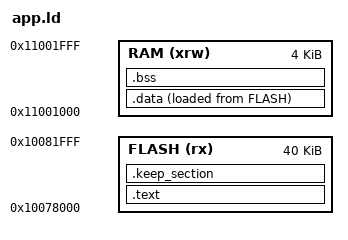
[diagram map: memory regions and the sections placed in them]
/*
 * Memory Spaces Definitions.
 *
 * Need modifying for a specific board. 
 *   FLASH.ORIGIN: starting address of flash
 *   FLASH.LENGTH: length of flash
 *   RAM.ORIGIN: starting address of RAM bank 0
 *   RAM.LENGTH: length of RAM bank 0
 *
 * The values below can be addressed in further linker scripts
 * using functions like 'ORIGIN(RAM)' or 'LENGTH(RAM)'.
 */
/*
*256K
*/
MEMORY
{
    FLASH (rx)      : ORIGIN = 0x10078000, LENGTH = 40K 
    RAM (xrw)       : ORIGIN = 0x11001000, LENGTH = 4K
}

/* 
 * The entry point is informative, for debuggers and simulators,
 * since the Cortex-M vector points to it anyway.
 */
ENTRY(app_init)


/* Sections Definitions */

SECTIONS
{
    /*
     * The program code is stored in the .text section, 
     * which goes to FLASH.
     */
    .text : ALIGN(4)
    {
        *(.text .text.*)            /* all remaining code */
 
        /* read-only data (constants) */
        *(.rodata .rodata.* .constdata .constdata.*)        

        KEEP(*(.eh_frame*))

        /*
         * Stub sections generated by the linker, to glue together 
         * ARM and Thumb code. .glue_7 is used for ARM code calling 
         * Thumb code, and .glue_7t is used for Thumb code calling 
         * ARM code. Apparently always generated by the linker, for some
         * architectures, so better leave them here.
         */
        *(.glue_7)
        *(.glue_7t)

    } >FLASH
    _sidata = LOADADDR(.data);
    .data : ALIGN(4)
    {
        /* This is used by the startup code to initialise the .data section */
        _sdata = . ;
        *(.data .data.*)
        . = ALIGN(4);
        /* This is used by the startup code to initialise the .data section */
        _edata = . ;

    } >RAM AT>FLASH
    
    /*
     * The uninitialised data sections. NOLOAD is used to avoid
     * the "section `.bss' type changed to PROGBITS" warning
     */

    /* The primary uninitialised data section. */
    .bss (NOLOAD) : ALIGN(4)
    {
        _sbss = .;      /* standard newlib definition */
        *(.bss .bss.*)
        *(COMMON)
        . = ALIGN(4);
        _ebss = .;        /* standard newlib definition */
    } >RAM

    .keep_section : ALIGN(4)
    {
        *(.keep_section)
        KEEP(*(.keep_section*))
    } >FLASH

}
